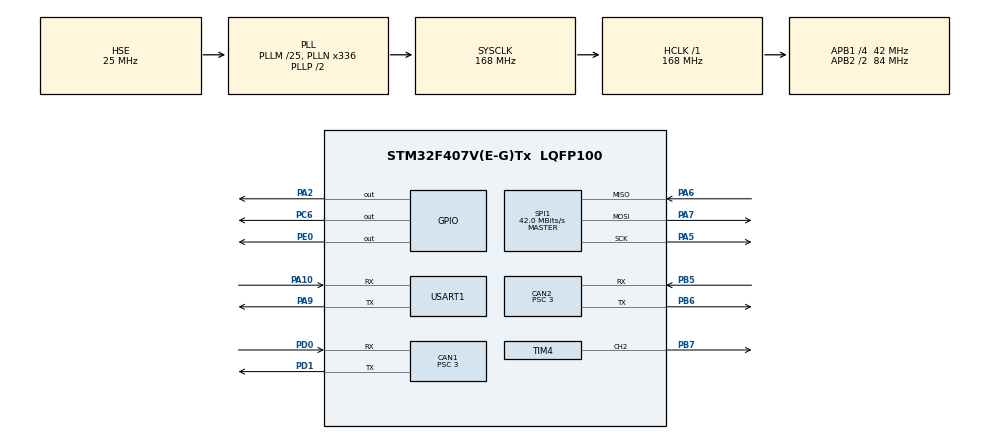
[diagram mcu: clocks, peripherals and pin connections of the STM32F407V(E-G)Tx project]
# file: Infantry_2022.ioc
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CAN1.BS1=CAN_BS1_8TQ
CAN1.BS2=CAN_BS2_5TQ
CAN1.CalculateBaudRate=1000000
CAN1.CalculateTimeBit=1000
CAN1.CalculateTimeQuantum=71.42857142857143
CAN1.Prescaler=3
CAN1.SJW=CAN_SJW_1TQ
CAN2.BS1=CAN_BS1_8TQ
CAN2.BS2=CAN_BS2_5TQ
CAN2.CalculateBaudRate=1000000
CAN2.CalculateTimeBit=1000
CAN2.CalculateTimeQuantum=71.42857142857143
CAN2.Prescaler=3
Dma.Request0=USART1_RX
Dma.Request1=USART1_TX
Dma.USART1_RX.0.Direction=DMA_PERIPH_TO_MEMORY
Dma.USART1_RX.0.FIFOMode=DMA_FIFOMODE_DISABLE
Dma.USART1_RX.0.Instance=DMA2_Stream2
Dma.USART1_RX.0.MemDataAlignment=DMA_MDATAALIGN_BYTE
Dma.USART1_RX.0.MemInc=DMA_MINC_ENABLE
Dma.USART1_RX.0.Mode=DMA_NORMAL
Dma.USART1_RX.0.PeriphDataAlignment=DMA_PDATAALIGN_BYTE
Dma.USART1_RX.0.PeriphInc=DMA_PINC_DISABLE
Dma.USART1_RX.0.Priority=DMA_PRIORITY_VERY_HIGH
Dma.USART1_TX.1.Direction=DMA_MEMORY_TO_PERIPH
Dma.USART1_TX.1.FIFOMode=DMA_FIFOMODE_DISABLE
Dma.USART1_TX.1.Instance=DMA2_Stream7
Dma.USART1_TX.1.MemDataAlignment=DMA_MDATAALIGN_BYTE
Dma.USART1_TX.1.MemInc=DMA_MINC_ENABLE
Dma.USART1_TX.1.Mode=DMA_NORMAL
Dma.USART1_TX.1.PeriphDataAlignment=DMA_PDATAALIGN_BYTE
Dma.USART1_TX.1.PeriphInc=DMA_PINC_DISABLE
Dma.USART1_TX.1.Priority=DMA_PRIORITY_MEDIUM
FREERTOS.Tasks01=defaultTask,0,128,StartDefaultTask,Default,NULL,Dynamic,NULL,NULL
Mcu.Family=STM32F4
Mcu.Name=STM32F407V(E-G)Tx
Mcu.Package=LQFP100
NVIC.CAN1_RX0_IRQn=true\:5\:0\:false\:true\:true\:1\:true\:true\:true
NVIC.CAN1_RX1_IRQn=true\:5\:0\:false\:false\:true\:true\:true\:true
NVIC.CAN2_RX0_IRQn=true\:5\:0\:false\:false\:true\:true\:true\:true
NVIC.CAN2_RX1_IRQn=true\:5\:0\:false\:false\:true\:true\:true\:true
NVIC.DMA2_Stream2_IRQn=true\:5\:0\:false\:false\:true\:true\:false\:true
NVIC.DMA2_Stream7_IRQn=true\:5\:0\:false\:false\:true\:true\:false\:true
NVIC.PriorityGroup=NVIC_PRIORITYGROUP_4
NVIC.TIM7_IRQn=true\:5\:0\:false\:true\:true\:2\:true\:true\:true
NVIC.USART1_IRQn=true\:5\:0\:false\:false\:true\:true\:true\:true
PA10.Mode=Asynchronous
PA10.Signal=USART1_RX
PA2.Signal=GPIO_Output
PA5.Mode=Full_Duplex_Master
PA5.Signal=SPI1_SCK
PA6.Mode=Full_Duplex_Master
PA6.Signal=SPI1_MISO
PA7.Mode=Full_Duplex_Master
PA7.Signal=SPI1_MOSI
PA9.Mode=Asynchronous
PA9.Signal=USART1_TX
PB5.Mode=CAN_Activate
PB5.Signal=CAN2_RX
PB6.Mode=CAN_Activate
PB6.Signal=CAN2_TX
PB7.Signal=S_TIM4_CH2
PC6.Signal=GPIO_Output
PD0.Mode=CAN_Activate
PD0.Signal=CAN1_RX
PD1.Mode=CAN_Activate
PD1.Signal=CAN1_TX
PD5.Signal=USART2_TX
PD6.Signal=USART2_RX
PD8.Signal=USART3_TX
PD9.Signal=USART3_RX
PE0.Signal=GPIO_Output
PH0-OSC_IN.Mode=HSE-External-Oscillator
PH0-OSC_IN.Signal=RCC_OSC_IN
PH1-OSC_OUT.Mode=HSE-External-Oscillator
PH1-OSC_OUT.Signal=RCC_OSC_OUT
ProjectManager.HeapSize=0x200
ProjectManager.StackSize=0x400
ProjectManager.TargetToolchain=MDK-ARM V5
RCC.48MHZClocksFreq_Value=84000000
RCC.AHBFreq_Value=168000000
RCC.APB1CLKDivider=RCC_HCLK_DIV4
RCC.APB1Freq_Value=42000000
RCC.APB1TimFreq_Value=84000000
RCC.APB2CLKDivider=RCC_HCLK_DIV2
RCC.APB2Freq_Value=84000000
RCC.APB2TimFreq_Value=168000000
RCC.CortexFreq_Value=168000000
RCC.HCLKFreq_Value=168000000
RCC.HSE_VALUE=25000000
RCC.HSI_VALUE=16000000
RCC.LSE_VALUE=32768
RCC.PLLM=25
RCC.PLLN=336
RCC.PLLSourceVirtual=RCC_PLLSOURCE_HSE
RCC.SYSCLKFreq_VALUE=168000000
RCC.SYSCLKSource=RCC_SYSCLKSOURCE_PLLCLK
RCC.VCOOutputFreq_Value=336000000
SH.S_TIM4_CH2.0=TIM4_CH2,PWM Generation2 CH2
SPI1.CalculateBaudRate=42.0 MBits/s
SPI1.Direction=SPI_DIRECTION_2LINES
SPI1.Mode=SPI_MODE_MASTER
SPI1.VirtualType=VM_MASTER
TIM4.AutoReloadPreload=TIM_AUTORELOAD_PRELOAD_ENABLE
TIM4.Channel-PWM\ Generation2\ CH2=TIM_CHANNEL_2
TIM4.OCPolarity_2=TIM_OCPOLARITY_LOW
TIM4.Period=499
TIM4.Prescaler=83
TIM4.Pulse-PWM\ Generation2\ CH2=0
TIM7.AutoReloadPreload=TIM_AUTORELOAD_PRELOAD_ENABLE
TIM7.Period=9999
TIM7.Prescaler=8399
TIM7.TIM_MasterOutputTrigger=TIM_TRGO_ENABLE
USART1.VirtualMode=VM_ASYNC
VP_FREERTOS_VS_CMSIS_V1.Mode=CMSIS_V1
VP_TIM4_VS_ClockSourceINT.Mode=Internal
VP_TIM6_VS_ClockSourceINT.Mode=Enable_Timer
VP_TIM7_VS_ClockSourceINT.Mode=Enable_Timer
board=custom

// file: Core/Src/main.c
/* USER CODE BEGIN Header */
/**
  ******************************************************************************
  * @file           : main.c
  * @brief          : Main program body
  ******************************************************************************
  * @attention
  *
  * <h2><center>&copy; Copyright (c) 2022 STMicroelectronics.
  * All rights reserved.</center></h2>
  *
  * This software component is licensed by ST under BSD 3-Clause license,
  * the "License"; You may not use this file except in compliance with the
  * License. You may obtain a copy of the License at:
  *                        opensource.org/licenses/BSD-3-Clause
  *
  ******************************************************************************
  */
/* USER CODE END Header */
#include "main.h"
#include "cmsis_os.h"
#include "can.h"
#include "dma.h"
#include "spi.h"
#include "tim.h"
#include "usart.h"
#include "gpio.h"

/* USER CODE BEGIN Includes */
#include "can1_ControlMotor.h"
/* USER CODE END Includes */

/* USER CODE BEGIN PD */
uint8_t temp[]="\r\n**** Serial Output Message by DMA ***\r\n   UART DMA Test \r\n   Zxiaoxuan";
/* USER CODE END PD */

void SystemClock_Config(void);
void MX_FREERTOS_Init(void);
static void MX_NVIC_Init(void);

int main(void)
{

  /* MCU Configuration--------------------------------------------------------*/

  /* Reset of all peripherals, Initializes the Flash interface and the Systick. */
  HAL_Init();

  /* Configure the system clock */
  SystemClock_Config();

  /* Initialize all configured peripherals */
  MX_GPIO_Init();
  MX_CAN1_Init();
  MX_SPI1_Init();
  MX_TIM7_Init();
  MX_TIM6_Init();
  MX_DMA_Init();
  MX_USART1_UART_Init();
  MX_TIM4_Init();
  MX_CAN2_Init();

  /* Initialize interrupts */
  MX_NVIC_Init();
  /* USER CODE BEGIN 2 */
	printf("\r\n**** Serial Output Message by DMA ***\r\n   UART DMA Test \r\n  �� ��������");
  PWM_LED();

  //Can1_ControlMotor_Exp_Mian();

  /* USER CODE END 2 */

  /* Call init function for freertos objects (in freertos.c) */
  MX_FREERTOS_Init();
  /* Start scheduler */
  osKernelStart();

  /* We should never get here as control is now taken by the scheduler */
  /* Infinite loop */
  while (1)
  {

  }
}

void SystemClock_Config(void)
{
  RCC_OscInitTypeDef RCC_OscInitStruct = {0};
  RCC_ClkInitTypeDef RCC_ClkInitStruct = {0};

  /** Configure the main internal regulator output voltage
  */
  __HAL_RCC_PWR_CLK_ENABLE();
  __HAL_PWR_VOLTAGESCALING_CONFIG(PWR_REGULATOR_VOLTAGE_SCALE1);
  /** Initializes the RCC Oscillators according to the specified parameters
  * in the RCC_OscInitTypeDef structure.
  */
  RCC_OscInitStruct.OscillatorType = RCC_OSCILLATORTYPE_HSE;
  RCC_OscInitStruct.HSEState = RCC_HSE_ON;
  RCC_OscInitStruct.PLL.PLLState = RCC_PLL_ON;
  RCC_OscInitStruct.PLL.PLLSource = RCC_PLLSOURCE_HSE;
  RCC_OscInitStruct.PLL.PLLM = 25;
  RCC_OscInitStruct.PLL.PLLN = 336;
  RCC_OscInitStruct.PLL.PLLP = RCC_PLLP_DIV2;
  RCC_OscInitStruct.PLL.PLLQ = 4;
  if (HAL_RCC_OscConfig(&RCC_OscInitStruct) != HAL_OK)
  {
    Error_Handler();
  }
  /** Initializes the CPU, AHB and APB buses clocks
  */
  RCC_ClkInitStruct.ClockType = RCC_CLOCKTYPE_HCLK|RCC_CLOCKTYPE_SYSCLK
                              |RCC_CLOCKTYPE_PCLK1|RCC_CLOCKTYPE_PCLK2;
  RCC_ClkInitStruct.SYSCLKSource = RCC_SYSCLKSOURCE_PLLCLK;
  RCC_ClkInitStruct.AHBCLKDivider = RCC_SYSCLK_DIV1;
  RCC_ClkInitStruct.APB1CLKDivider = RCC_HCLK_DIV4;
  RCC_ClkInitStruct.APB2CLKDivider = RCC_HCLK_DIV2;

  if (HAL_RCC_ClockConfig(&RCC_ClkInitStruct, FLASH_LATENCY_5) != HAL_OK)
  {
    Error_Handler();
  }
}

/**
  * @brief NVIC Configuration.
  * @retval None
  */
static void MX_NVIC_Init(void)
{
  /* CAN1_RX0_IRQn interrupt configuration */
  HAL_NVIC_SetPriority(CAN1_RX0_IRQn, 5, 0);
  HAL_NVIC_EnableIRQ(CAN1_RX0_IRQn);
  /* TIM7_IRQn interrupt configuration */
  HAL_NVIC_SetPriority(TIM7_IRQn, 5, 0);
  HAL_NVIC_EnableIRQ(TIM7_IRQn);
}

void Error_Handler(void)
{
  __disable_irq();
  while (1)
  {
  }
}
